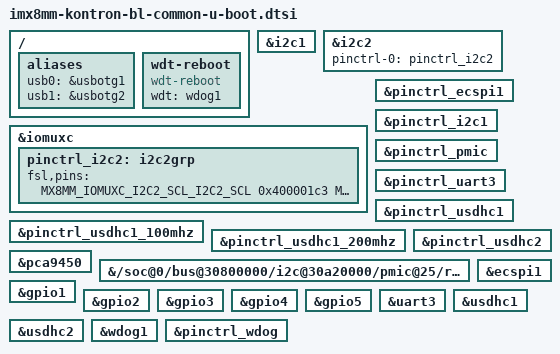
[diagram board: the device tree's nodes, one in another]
// SPDX-License-Identifier: GPL-2.0+ OR MIT
/*
 * Copyright (C) 2019 Kontron Electronics GmbH
 */

#include "imx8mm-u-boot.dtsi"

/ {
	aliases {
		usb0 = &usbotg1;
		usb1 = &usbotg2;
	};

	wdt-reboot {
		compatible = "wdt-reboot";
		wdt = <&wdog1>;
		bootph-pre-ram;
	};
};

&i2c1 {
	bootph-pre-ram;
	bootph-all;
};

&i2c2 {
	status = "okay";
	pinctrl-names = "default";
	pinctrl-0 = <&pinctrl_i2c2>;
};

&iomuxc {
	pinctrl_i2c2: i2c2grp {
		fsl,pins = <
			MX8MM_IOMUXC_I2C2_SCL_I2C2_SCL		0x400001c3
			MX8MM_IOMUXC_I2C2_SDA_I2C2_SDA		0x400001c3
		>;
	};
};

&pinctrl_ecspi1 {
	bootph-pre-ram;
};

&pinctrl_i2c1 {
	bootph-pre-ram;
};

&pinctrl_pmic {
	bootph-pre-ram;
};

&pinctrl_uart3 {
	bootph-pre-ram;
	bootph-all;
};

&pinctrl_usdhc1 {
	bootph-pre-ram;
};

&pinctrl_usdhc1_100mhz {
	bootph-pre-ram;
};

&pinctrl_usdhc1_200mhz {
	bootph-pre-ram;
};

&pinctrl_usdhc2 {
	bootph-pre-ram;
};

&pca9450 {
	bootph-pre-ram;
};

&{/soc@0/bus@30800000/i2c@30a20000/pmic@25/regulators} {
	bootph-pre-ram;
};

&ecspi1 {
	bootph-pre-ram;
};

&gpio1 {
	bootph-pre-ram;
};

&gpio2 {
	bootph-pre-ram;
};

&gpio3 {
	bootph-pre-ram;
};

&gpio4 {
	bootph-pre-ram;
};

&gpio5 {
	bootph-pre-ram;
};

&uart3 {
	bootph-pre-ram;
	bootph-all;
};

&usdhc1 {
	bootph-pre-ram;
};

&usdhc2 {
	bootph-pre-ram;
};

&wdog1 {
	bootph-pre-ram;
};

&pinctrl_wdog {
	bootph-pre-ram;
};
